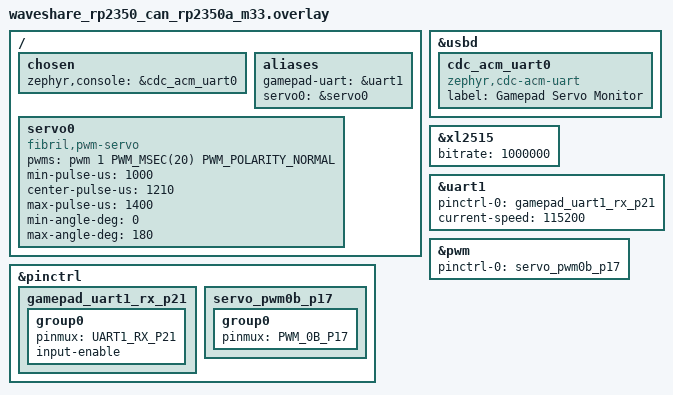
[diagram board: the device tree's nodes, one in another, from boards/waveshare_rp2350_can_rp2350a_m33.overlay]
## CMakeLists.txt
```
cmake_minimum_required(VERSION 3.20.0)
find_package(Zephyr REQUIRED HINTS $ENV{ZEPHYR_BASE})
project(gamepad_servo_sample)
target_sources(app PRIVATE src/main.c src/can_servo_control.c)
```

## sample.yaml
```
sample:
  name: RP2350-CAN gamepad-controlled PWM servo
common:
  build_only: true
  integration_platforms:
    - waveshare_rp2350_can/rp2350a/m33
  tags: [can, gamepad, servo, pwm, uart]
tests:
  sample.app.gamepad_servo: {}
```

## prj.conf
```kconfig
CONFIG_PWM=y
CONFIG_SERVO=y
CONFIG_CAN=y
CONFIG_SERIAL=y
CONFIG_COBS=y
CONFIG_ESP_NOW_GAMEPAD_BRIDGE=y
CONFIG_ESP_NOW_GAMEPAD_BRIDGE_TIMEOUT_MS=100

CONFIG_LOG=y
CONFIG_CONSOLE=y
CONFIG_UART_CONSOLE=y
CONFIG_SHELL_BACKEND_SERIAL=n
CONFIG_USB_DEVICE_STACK_NEXT=y
CONFIG_CDC_ACM_SERIAL_INITIALIZE_AT_BOOT=y
CONFIG_CDC_ACM_SERIAL_PRODUCT_STRING="RP2350 Gamepad Servo Monitor"
CONFIG_UART_LINE_CTRL=y
# CDC ACM is the log transport, so logging from the transport itself must stay off.
CONFIG_USBD_CDC_ACM_LOG_LEVEL_OFF=y
```

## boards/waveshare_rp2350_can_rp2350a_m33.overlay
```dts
#include <zephyr/dt-bindings/pinctrl/rpi-pico-rp2350a-pinctrl.h>
#include <zephyr/dt-bindings/pwm/pwm.h>

/ {
	chosen {
		zephyr,console = &cdc_acm_uart0;
	};

	aliases {
		gamepad-uart = &uart1;
		servo0 = &servo0;
	};

	servo0: servo0 {
		compatible = "fibril,pwm-servo";
		/* Header pin 22 is GP17 / PWM0B (channel 1); use a 50 Hz frame. */
		pwms = <&pwm 1 PWM_MSEC(20) PWM_POLARITY_NORMAL>;
		min-pulse-us = <1000>;
		center-pulse-us = <1210>;
		max-pulse-us = <1400>;
		min-angle-deg = <0>;
		max-angle-deg = <180>;
	};
};

zephyr_udc0: &usbd {
	status = "okay";

	cdc_acm_uart0: cdc_acm_uart0 {
		compatible = "zephyr,cdc-acm-uart";
		label = "Gamepad Servo Monitor";
	};
};

&xl2515 {
	/* The fault-contained driver must not stop UART/PWM control even when the
	 * CAN bus, controller interrupt, or SPI path fails.
	 */
	bitrate = <1000000>;
	status = "okay";
};

&pinctrl {
	gamepad_uart1_rx_p21: gamepad_uart1_rx_p21 {
		group0 {
			/* Header pin 27 is GP21 / UART1 RX; TX is intentionally unused. */
			pinmux = <UART1_RX_P21>;
			input-enable;
		};
	};

	servo_pwm0b_p17: servo_pwm0b_p17 {
		group0 {
			pinmux = <PWM_0B_P17>;
		};
	};
};

&uart1 {
	pinctrl-0 = <&gamepad_uart1_rx_p21>;
	pinctrl-names = "default";
	current-speed = <115200>;
	/delete-property/ hw-flow-control;
	status = "okay";
};

&pwm {
	/* Replace the board pin group so GP21 can be owned exclusively by UART1 RX. */
	pinctrl-0 = <&servo_pwm0b_p17>;
	pinctrl-names = "default";
	status = "okay";
};
```

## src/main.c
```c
/* SPDX-License-Identifier: Apache-2.0 */
#include <zephyr/device.h>
#include <zephyr/drivers/can.h>
#include <zephyr/drivers/gpio.h>
#include <zephyr/drivers/pwm.h>
#include <zephyr/kernel.h>
#include <zephyr/logging/log.h>
#include <zephyr/sys/atomic.h>

#include <drivers/servo.h>
#include <esp_now_gamepad_bridge/gamepad_bridge.h>

#include "can_servo_control.h"

LOG_MODULE_REGISTER(gamepad_servo, LOG_LEVEL_INF);

#define SERVO_NODE DT_ALIAS(servo0)
#define GAMEPAD_UART_NODE DT_ALIAS(gamepad_uart)
#define CAN_NODE DT_ALIAS(can0)
#define LED_NODE DT_ALIAS(led0)

#define CONTROL_PERIOD_MS 10U
#define LED_BLINK_HALF_PERIOD_MS 500U
#define PULSE_STEP_US 5U
#define LOG_STATUS_PERIOD_MS 250U
#define CAN_STATUS_PERIOD_MS 50U

#define SERVO_MIN_US DT_PROP(SERVO_NODE, min_pulse_us)
#define SERVO_CENTER_US DT_PROP(SERVO_NODE, center_pulse_us)
#define SERVO_MAX_US DT_PROP(SERVO_NODE, max_pulse_us)
#define SERVO_MIN_ANGLE_DEG ((float)(int32_t)DT_PROP(SERVO_NODE, min_angle_deg))
#define SERVO_MAX_ANGLE_DEG ((float)(int32_t)DT_PROP(SERVO_NODE, max_angle_deg))
#define SERVO_PERIOD_US (DT_PWMS_PERIOD(SERVO_NODE) / 1000U)

BUILD_ASSERT(SERVO_PERIOD_US == 20000U,
	     "duty reporting assumes a 20 ms servo frame");

CAN_MSGQ_DEFINE(can_rx_queue, 8);

static const struct gpio_dt_spec led = GPIO_DT_SPEC_GET(LED_NODE, gpios);
static atomic_t can_tx_failures;

static uint32_t clamp_add(uint32_t value, uint32_t step, uint32_t maximum)
{
	return value > maximum - step ? maximum : value + step;
}

static uint32_t clamp_sub(uint32_t value, uint32_t step, uint32_t minimum)
{
	return value < minimum + step ? minimum : value - step;
}

static void can_tx_callback(const struct device *dev, int error,
			    void *user_data)
{
	ARG_UNUSED(dev);
	ARG_UNUSED(user_data);

	if (error != 0) {
		atomic_inc(&can_tx_failures);
	}
}

static int start_can(const struct device *can)
{
	const struct can_filter command_filter = {
		.id = CAN_SERVO_COMMAND_ID,
		.mask = CAN_STD_ID_MASK,
		.flags = 0,
	};
	const struct can_filter broadcast_filter = {
		.id = CAN_SERVO_BROADCAST_ID,
		.mask = CAN_STD_ID_MASK,
		.flags = 0,
	};
	int command_filter_id;
	int broadcast_filter_id;
	int ret;

	if (!device_is_ready(can)) {
		return -ENODEV;
	}

	command_filter_id =
		can_add_rx_filter_msgq(can, &can_rx_queue, &command_filter);
	if (command_filter_id < 0) {
		return command_filter_id;
	}

	broadcast_filter_id =
		can_add_rx_filter_msgq(can, &can_rx_queue, &broadcast_filter);
	if (broadcast_filter_id < 0) {
		can_remove_rx_filter(can, command_filter_id);
		return broadcast_filter_id;
	}

	ret = can_start(can);
	if (ret < 0) {
		can_remove_rx_filter(can, broadcast_filter_id);
		can_remove_rx_filter(can, command_filter_id);
	}
	return ret;
}

static int process_can_frames(const struct device *servo,
			      struct can_servo_control_state *control)
{
	struct can_frame frame;

	while (k_msgq_get(&can_rx_queue, &frame, K_NO_WAIT) == 0) {
		enum can_servo_output_action action = can_servo_handle_frame(
			control, &frame, SERVO_MIN_ANGLE_DEG,
			SERVO_MAX_ANGLE_DEG);
		int ret;

		switch (action) {
		case CAN_SERVO_OUTPUT_ATTACH_CURRENT:
			ret = servo_set_angle(servo, control->current_angle_deg);
			if (ret < 0) {
				return ret;
			}
			break;
		case CAN_SERVO_OUTPUT_DISABLE:
			ret = servo_disable(servo);
			if (ret < 0) {
				return ret;
			}
			break;
		default:
			break;
		}
	}

	return 0;
}

static int send_can_status(const struct device *can,
			   const struct can_servo_control_state *control)
{
	struct can_frame frame;
	int ret;

	can_servo_encode_status(control, &frame);
	ret = can_send(can, &frame, K_NO_WAIT, can_tx_callback, NULL);
	if (ret < 0) {
		atomic_inc(&can_tx_failures);
	}
	return ret;
}

static void log_status(const struct gamepad_state *gamepad,
		       const struct can_servo_control_state *control)
{
	/* centi-percent avoids floating-point formatting on the serial log path. */
	uint32_t duty_centi_percent = control->pulse_us * 10000U / SERVO_PERIOD_US;
	int32_t target_tenths = (int32_t)(control->target_angle_deg * 10.0f);
	int32_t current_tenths = (int32_t)(control->current_angle_deg * 10.0f);

	LOG_INF("source=%s connected=%u seq=%u buttons=0x%04x pulse=%u us "
		"duty=%u.%02u%% target=%d ddeg current=%d ddeg state=%s "
		"can_tx_failures=%u",
		can_servo_source_name(control->source), gamepad->connected,
		gamepad->seq, gamepad->buttons, control->pulse_us,
		duty_centi_percent / 100U, duty_centi_percent % 100U,
		target_tenths, current_tenths,
		can_servo_status_name(can_servo_get_status_state(control)),
		(uint32_t)atomic_get(&can_tx_failures));
}

int main(void)
{
	const struct device *servo = DEVICE_DT_GET(SERVO_NODE);
	const struct device *uart = DEVICE_DT_GET(GAMEPAD_UART_NODE);
	const struct device *can = DEVICE_DT_GET(CAN_NODE);
	struct can_servo_control_state control;
	int64_t next_log_status_ms = 0;
	int64_t next_can_status_ms = 0;
	int64_t next_led_toggle_ms = 0;
	int64_t previous_control_ms;
	bool can_started;
	bool was_connected = false;
	bool led_on = true;
	int ret;

	if (!gpio_is_ready_dt(&led)) {
		LOG_ERR("LED GPIO is not ready");
		return -ENODEV;
	}

	ret = gpio_pin_configure_dt(&led, GPIO_OUTPUT_ACTIVE);
	if (ret < 0) {
		LOG_ERR("LED GPIO configuration failed (%d)", ret);
		return ret;
	}

	if (!device_is_ready(servo)) {
		LOG_ERR("Servo is not ready");
		return -ENODEV;
	}

	ret = gamepad_bridge_init(uart);
	if (ret == 0) {
		ret = gamepad_bridge_start();
	}
	if (ret < 0) {
		LOG_ERR("Gamepad receiver startup failed (%d)", ret);
		return ret;
	}

	ret = servo_set_pulse(servo, SERVO_CENTER_US);
	if (ret < 0) {
		LOG_ERR("Initial servo command failed (%d)", ret);
		return ret;
	}
	can_servo_state_init(&control, SERVO_CENTER_US, SERVO_MIN_US,
			     SERVO_MAX_US, SERVO_MIN_ANGLE_DEG,
			     SERVO_MAX_ANGLE_DEG);

	ret = start_can(can);
	can_started = ret == 0;

	previous_control_ms = k_uptime_get();
	if (can_started) {
		LOG_INF("Ready: UART D-pad and Classic CAN servo ID %u at 1 Mbps",
			CAN_SERVO_ID);
	} else {
		LOG_ERR("CAN startup failed (%d); UART/PWM control remains available",
			ret);
	}

	while (true) {
		struct gamepad_state gamepad;
		int64_t now_ms;
		int64_t elapsed_ms;
		uint32_t next_pulse_us = control.pulse_us;
		bool up;
		bool down;

		ret = gamepad_bridge_get_state(&gamepad);
		if (ret < 0) {
			LOG_ERR("Gamepad state read failed (%d)", ret);
			break;
		}

		now_ms = k_uptime_get();
		elapsed_ms = now_ms - previous_control_ms;
		previous_control_ms = now_ms;

		/* CAN is processed before UART, so an active D-pad command in this
		 * iteration is the deterministic last command and takes ownership.
		 */
		if (can_started) {
			ret = process_can_frames(servo, &control);
			if (ret < 0) {
				LOG_ERR("CAN servo command failed (%d)", ret);
				break;
			}
		}

		up = (gamepad.buttons & GAMEPAD_BUTTON_DPAD_UP) != 0U;
		down = (gamepad.buttons & GAMEPAD_BUTTON_DPAD_DOWN) != 0U;
		if (gamepad.connected && up != down) {
			if (up) {
				next_pulse_us = clamp_add(control.pulse_us,
						  PULSE_STEP_US, SERVO_MAX_US);
			} else {
				next_pulse_us = clamp_sub(control.pulse_us,
						  PULSE_STEP_US, SERVO_MIN_US);
			}
			if (next_pulse_us != control.pulse_us) {
				ret = servo_set_pulse(servo, next_pulse_us);
				if (ret < 0) {
					LOG_ERR("UART servo command failed (%d)", ret);
					break;
				}
				can_servo_take_uart_pulse(
					&control, next_pulse_us, SERVO_MIN_US,
					SERVO_MAX_US, SERVO_MIN_ANGLE_DEG,
					SERVO_MAX_ANGLE_DEG);
			}
		}

		if (!gamepad.connected && was_connected &&
		    control.source == CAN_SERVO_SOURCE_UART) {
			ret = servo_set_pulse(servo, SERVO_CENTER_US);
			if (ret < 0) {
				LOG_ERR("UART timeout center command failed (%d)", ret);
				break;
			}
			can_servo_take_uart_pulse(
				&control, SERVO_CENTER_US, SERVO_MIN_US,
				SERVO_MAX_US, SERVO_MIN_ANGLE_DEG,
				SERVO_MAX_ANGLE_DEG);
			LOG_WRN("Gamepad link lost; returning UART-owned servo to center");
		}

		if (can_servo_step(&control, (float)elapsed_ms / 1000.0f,
				   SERVO_MIN_US, SERVO_MAX_US,
				   SERVO_MIN_ANGLE_DEG,
				   SERVO_MAX_ANGLE_DEG)) {
			ret = servo_set_angle(servo, control.current_angle_deg);
			if (ret < 0) {
				LOG_ERR("CAN slew command failed (%d)", ret);
				break;
			}
		}

		if (can_started &&
		    (control.status_requested || now_ms >= next_can_status_ms)) {
			bool periodic = now_ms >= next_can_status_ms;

			if (send_can_status(can, &control) == 0) {
				control.status_requested = false;
			}
			if (periodic) {
				next_can_status_ms = now_ms + CAN_STATUS_PERIOD_MS;
			}
		}

		if (gamepad.connected) {
			if (next_led_toggle_ms == 0) {
				next_led_toggle_ms = now_ms + LED_BLINK_HALF_PERIOD_MS;
			} else if (now_ms >= next_led_toggle_ms) {
				led_on = !led_on;
				ret = gpio_pin_set_dt(&led, led_on ? 1 : 0);
				if (ret < 0) {
					LOG_ERR("LED update failed (%d)", ret);
					break;
				}
				next_led_toggle_ms =
					now_ms + LED_BLINK_HALF_PERIOD_MS;
			}
		} else {
			next_led_toggle_ms = 0;
			if (!led_on) {
				ret = gpio_pin_set_dt(&led, 1);
				if (ret < 0) {
					LOG_ERR("LED update failed (%d)", ret);
					break;
				}
				led_on = true;
			}
		}

		was_connected = gamepad.connected;
		if (now_ms >= next_log_status_ms) {
			log_status(&gamepad, &control);
			next_log_status_ms = now_ms + LOG_STATUS_PERIOD_MS;
		}
		k_sleep(K_MSEC(CONTROL_PERIOD_MS));
	}

	if (control.attached && servo_set_pulse(servo, SERVO_CENTER_US) < 0) {
		LOG_ERR("Could not return servo to center after failure");
	}
	if (gpio_pin_set_dt(&led, 1) < 0) {
		LOG_ERR("Could not turn LED on after failure");
	}
	return ret;
}
```

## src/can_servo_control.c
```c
/* SPDX-License-Identifier: Apache-2.0 */
#include "can_servo_control.h"

#include <limits.h>
#include <string.h>

#include <zephyr/sys/util.h>

#define CAN_SERVO_CMD_SET_POSITION 0x00U
#define CAN_SERVO_CMD_HOLD 0x01U
#define CAN_SERVO_CMD_DETACH 0x02U
#define CAN_SERVO_CMD_REQUEST_STATUS 0x03U
#define CAN_SERVO_ANGLE_EPSILON_DEG 0.01f

static float abs_float(float value)
{
	return value < 0.0f ? -value : value;
}

static float clamp_angle(float angle_deg, float min_angle_deg,
			 float max_angle_deg)
{
	return CLAMP(angle_deg, min_angle_deg, max_angle_deg);
}

float can_servo_pulse_to_angle(uint32_t pulse_us, uint32_t min_pulse_us,
			       uint32_t max_pulse_us, float min_angle_deg,
			       float max_angle_deg)
{
	uint32_t pulse = CLAMP(pulse_us, min_pulse_us, max_pulse_us);
	double fraction = (double)(pulse - min_pulse_us) /
			  (double)(max_pulse_us - min_pulse_us);

	return (float)((double)min_angle_deg +
		       fraction * ((double)max_angle_deg - (double)min_angle_deg));
}

uint32_t can_servo_angle_to_pulse(float angle_deg, uint32_t min_pulse_us,
				  uint32_t max_pulse_us, float min_angle_deg,
				  float max_angle_deg)
{
	double angle = clamp_angle(angle_deg, min_angle_deg, max_angle_deg);
	double fraction = (angle - (double)min_angle_deg) /
			  ((double)max_angle_deg - (double)min_angle_deg);
	double pulse_us = min_pulse_us +
			  fraction * (max_pulse_us - min_pulse_us);

	return (uint32_t)(pulse_us + 0.5);
}

void can_servo_state_init(struct can_servo_control_state *state,
			  uint32_t initial_pulse_us, uint32_t min_pulse_us,
			  uint32_t max_pulse_us, float min_angle_deg,
			  float max_angle_deg)
{
	memset(state, 0, sizeof(*state));
	state->pulse_us = CLAMP(initial_pulse_us, min_pulse_us, max_pulse_us);
	state->current_angle_deg = can_servo_pulse_to_angle(
		state->pulse_us, min_pulse_us, max_pulse_us, min_angle_deg,
		max_angle_deg);
	state->target_angle_deg = state->current_angle_deg;
	state->attached = true;
}

static int32_t decode_i16_le(const uint8_t *data)
{
	uint32_t raw = (uint32_t)data[0] | ((uint32_t)data[1] << 8);

	return (raw & 0x8000U) != 0U ? (int32_t)raw - 0x10000 : (int32_t)raw;
}

static uint16_t decode_u16_le(const uint8_t *data)
{
	return (uint16_t)data[0] | ((uint16_t)data[1] << 8);
}

enum can_servo_output_action
can_servo_handle_frame(struct can_servo_control_state *state,
		       const struct can_frame *frame, float min_angle_deg,
		       float max_angle_deg)
{
	bool broadcast;
	uint8_t command;

	if ((frame->flags & (CAN_FRAME_IDE | CAN_FRAME_RTR)) != 0U) {
		return CAN_SERVO_OUTPUT_NONE;
	}

	broadcast = frame->id == CAN_SERVO_BROADCAST_ID;
	if (!broadcast && frame->id != CAN_SERVO_COMMAND_ID) {
		return CAN_SERVO_OUTPUT_NONE;
	}
	if (frame->dlc == 0U) {
		return CAN_SERVO_OUTPUT_NONE;
	}

	command = frame->data[0];
	if (broadcast && command != CAN_SERVO_CMD_DETACH) {
		return CAN_SERVO_OUTPUT_NONE;
	}

	switch (command) {
	case CAN_SERVO_CMD_SET_POSITION: {
		float requested_angle;
		float accepted_angle;

		if (frame->dlc < 5U) {
			state->rejected = true;
			return CAN_SERVO_OUTPUT_NONE;
		}

		requested_angle = (float)decode_i16_le(&frame->data[1]) * 0.1f;
		accepted_angle = clamp_angle(requested_angle, min_angle_deg,
					     max_angle_deg);
		state->target_angle_deg = accepted_angle;
		state->speed_limit_dps =
			(float)decode_u16_le(&frame->data[3]) * 0.1f;
		state->source = CAN_SERVO_SOURCE_CAN;
		state->clamped = requested_angle != accepted_angle;
		state->rejected = false;
		if (!state->attached) {
			state->attached = true;
			return CAN_SERVO_OUTPUT_ATTACH_CURRENT;
		}
		return CAN_SERVO_OUTPUT_NONE;
	}
	case CAN_SERVO_CMD_HOLD:
		state->target_angle_deg = state->current_angle_deg;
		state->speed_limit_dps = 0.0f;
		state->source = CAN_SERVO_SOURCE_CAN;
		state->rejected = false;
		return CAN_SERVO_OUTPUT_NONE;
	case CAN_SERVO_CMD_DETACH:
		state->attached = false;
		state->target_angle_deg = state->current_angle_deg;
		state->source = CAN_SERVO_SOURCE_CAN;
		state->rejected = false;
		return CAN_SERVO_OUTPUT_DISABLE;
	case CAN_SERVO_CMD_REQUEST_STATUS:
		state->status_requested = true;
		state->rejected = false;
		return CAN_SERVO_OUTPUT_NONE;
	default:
		state->rejected = true;
		return CAN_SERVO_OUTPUT_NONE;
	}
}

bool can_servo_step(struct can_servo_control_state *state, float dt_sec,
		    uint32_t min_pulse_us, uint32_t max_pulse_us,
		    float min_angle_deg, float max_angle_deg)
{
	float delta;
	float next_angle;

	if (state->source != CAN_SERVO_SOURCE_CAN || !state->attached) {
		return false;
	}

	delta = state->target_angle_deg - state->current_angle_deg;
	if (abs_float(delta) <= CAN_SERVO_ANGLE_EPSILON_DEG) {
		return false;
	}

	if (state->speed_limit_dps == 0.0f) {
		next_angle = state->target_angle_deg;
	} else {
		float max_delta = state->speed_limit_dps * MAX(dt_sec, 0.0f);

		if (max_delta <= 0.0f) {
			return false;
		}
		if (max_delta >= abs_float(delta)) {
			next_angle = state->target_angle_deg;
		} else {
			next_angle = state->current_angle_deg +
				     (delta > 0.0f ? max_delta : -max_delta);
		}
	}

	state->current_angle_deg = next_angle;
	state->pulse_us = can_servo_angle_to_pulse(
		next_angle, min_pulse_us, max_pulse_us, min_angle_deg,
		max_angle_deg);
	return true;
}

void can_servo_take_uart_pulse(struct can_servo_control_state *state,
			       uint32_t pulse_us, uint32_t min_pulse_us,
			       uint32_t max_pulse_us, float min_angle_deg,
			       float max_angle_deg)
{
	state->pulse_us = CLAMP(pulse_us, min_pulse_us, max_pulse_us);
	state->current_angle_deg = can_servo_pulse_to_angle(
		state->pulse_us, min_pulse_us, max_pulse_us, min_angle_deg,
		max_angle_deg);
	state->target_angle_deg = state->current_angle_deg;
	state->speed_limit_dps = 0.0f;
	state->source = CAN_SERVO_SOURCE_UART;
	state->attached = true;
}

enum can_servo_status_state
can_servo_get_status_state(const struct can_servo_control_state *state)
{
	if (!state->attached) {
		return CAN_SERVO_STATUS_DETACHED;
	}
	if (abs_float(state->target_angle_deg - state->current_angle_deg) >
	    CAN_SERVO_ANGLE_EPSILON_DEG) {
		return CAN_SERVO_STATUS_MOVING;
	}
	return CAN_SERVO_STATUS_HOLDING;
}

static int16_t angle_to_tenths(float angle_deg)
{
	float scaled = angle_deg * 10.0f;
	int32_t rounded;

	if (scaled >= INT16_MAX) {
		return INT16_MAX;
	}
	if (scaled <= INT16_MIN) {
		return INT16_MIN;
	}
	rounded = (int32_t)(scaled + (scaled >= 0.0f ? 0.5f : -0.5f));
	return (int16_t)rounded;
}

static void encode_i16_le(uint8_t *data, int16_t value)
{
	uint16_t raw = (uint16_t)value;

	data[0] = (uint8_t)raw;
	data[1] = (uint8_t)(raw >> 8);
}

void can_servo_encode_status(const struct can_servo_control_state *state,
			     struct can_frame *frame)
{
	memset(frame, 0, sizeof(*frame));
	frame->id = CAN_SERVO_STATUS_ID;
	frame->dlc = 5U;
	frame->data[0] = (uint8_t)can_servo_get_status_state(state) |
			 (state->clamped ? 0x10U : 0U) |
			 (state->rejected ? 0x20U : 0U);
	encode_i16_le(&frame->data[1], angle_to_tenths(state->target_angle_deg));
	encode_i16_le(&frame->data[3], angle_to_tenths(state->current_angle_deg));
}

const char *can_servo_source_name(enum can_servo_control_source source)
{
	switch (source) {
	case CAN_SERVO_SOURCE_UART:
		return "uart";
	case CAN_SERVO_SOURCE_CAN:
		return "can";
	default:
		return "none";
	}
}

const char *can_servo_status_name(enum can_servo_status_state state)
{
	switch (state) {
	case CAN_SERVO_STATUS_MOVING:
		return "moving";
	case CAN_SERVO_STATUS_DETACHED:
		return "detached";
	default:
		return "holding";
	}
}
```

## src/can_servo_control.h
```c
/* SPDX-License-Identifier: Apache-2.0 */
#ifndef GAMEPAD_SERVO_CAN_SERVO_CONTROL_H_
#define GAMEPAD_SERVO_CAN_SERVO_CONTROL_H_

#include <stdbool.h>
#include <stdint.h>

#include <zephyr/drivers/can.h>

#define CAN_SERVO_ID 1U
#define CAN_SERVO_COMMAND_ID (0x300U + CAN_SERVO_ID)
#define CAN_SERVO_BROADCAST_ID 0x300U
#define CAN_SERVO_STATUS_ID (0x380U + CAN_SERVO_ID)

enum can_servo_control_source {
	CAN_SERVO_SOURCE_NONE,
	CAN_SERVO_SOURCE_UART,
	CAN_SERVO_SOURCE_CAN,
};

enum can_servo_output_action {
	CAN_SERVO_OUTPUT_NONE,
	CAN_SERVO_OUTPUT_ATTACH_CURRENT,
	CAN_SERVO_OUTPUT_DISABLE,
};

enum can_servo_status_state {
	CAN_SERVO_STATUS_HOLDING = 0,
	CAN_SERVO_STATUS_MOVING = 1,
	CAN_SERVO_STATUS_DETACHED = 2,
};

struct can_servo_control_state {
	enum can_servo_control_source source;
	float current_angle_deg;
	float target_angle_deg;
	float speed_limit_dps;
	uint32_t pulse_us;
	bool attached;
	bool clamped;
	bool rejected;
	bool status_requested;
};

void can_servo_state_init(struct can_servo_control_state *state,
			  uint32_t initial_pulse_us, uint32_t min_pulse_us,
			  uint32_t max_pulse_us, float min_angle_deg,
			  float max_angle_deg);

enum can_servo_output_action
can_servo_handle_frame(struct can_servo_control_state *state,
		       const struct can_frame *frame, float min_angle_deg,
		       float max_angle_deg);

bool can_servo_step(struct can_servo_control_state *state, float dt_sec,
		    uint32_t min_pulse_us, uint32_t max_pulse_us,
		    float min_angle_deg, float max_angle_deg);

void can_servo_take_uart_pulse(struct can_servo_control_state *state,
			       uint32_t pulse_us, uint32_t min_pulse_us,
			       uint32_t max_pulse_us, float min_angle_deg,
			       float max_angle_deg);

float can_servo_pulse_to_angle(uint32_t pulse_us, uint32_t min_pulse_us,
			       uint32_t max_pulse_us, float min_angle_deg,
			       float max_angle_deg);

uint32_t can_servo_angle_to_pulse(float angle_deg, uint32_t min_pulse_us,
				  uint32_t max_pulse_us, float min_angle_deg,
				  float max_angle_deg);

enum can_servo_status_state
can_servo_get_status_state(const struct can_servo_control_state *state);

void can_servo_encode_status(const struct can_servo_control_state *state,
			     struct can_frame *frame);

const char *can_servo_source_name(enum can_servo_control_source source);
const char *can_servo_status_name(enum can_servo_status_state state);

#endif /* GAMEPAD_SERVO_CAN_SERVO_CONTROL_H_ */
```
